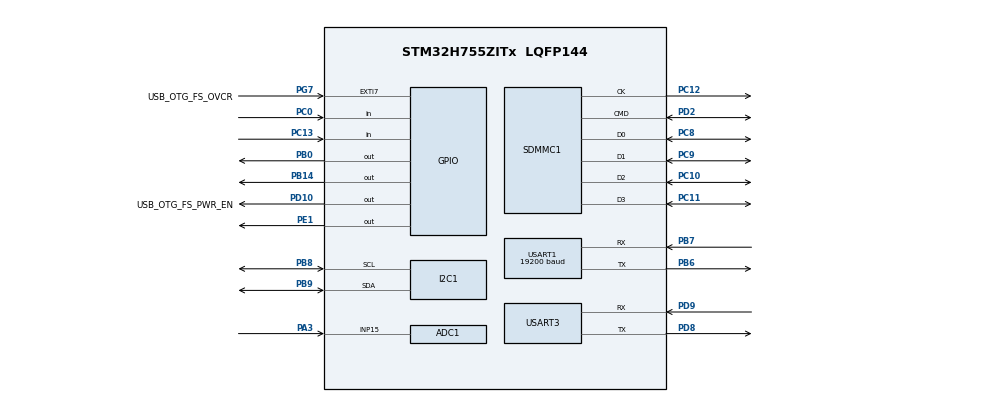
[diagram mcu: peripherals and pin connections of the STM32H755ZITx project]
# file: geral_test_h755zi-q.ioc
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ADC1.Channel-0\#ChannelRegularConversion=ADC_CHANNEL_15
ADC1.NbrOfConversionFlag=1
ADC1.OffsetNumber-0\#ChannelRegularConversion=ADC_OFFSET_NONE
ADC1.OffsetSignedSaturation-0\#ChannelRegularConversion=DISABLE
ADC1.Rank-0\#ChannelRegularConversion=1
ADC1.Resolution=ADC_RESOLUTION_8B
ADC1.SamplingTime-0\#ChannelRegularConversion=ADC_SAMPLETIME_1CYCLE_5
ADC1.master=1
CortexM4.IPs=FATFS_M4\:I,FREERTOS_M4\:I,IWDG2\:I,RCC,WWDG2\:I,DMA,BDMA,MDMA,NVIC2\:I,DEBUG,PDM2PCM_M4\:I,PWR,RESMGR_UTILITY,SYS_M4\:I,USB_DEVICE_M4\:I,USB_HOST_M4\:I,CORTEX_M4\:I,GPIO,OPENAMP_M4\:I,VREFBUF,NUCLEO-H755ZI-Q
CortexM7.IPs=FATFS_M7\:I,FREERTOS_M7\:I,IWDG1\:I,RCC\:I,WWDG1\:I,DMA\:I,BDMA\:I,MDMA\:I,NVIC1\:I,SYS\:I,CORTEX_M7\:I,DEBUG\:I,PDM2PCM_M7\:I,PWR\:I,RESMGR_UTILITY\:I,USB_DEVICE_M7\:I,USB_HOST_M7\:I,GPIO\:I,OPENAMP_M7\:I,VREFBUF\:I,NUCLEO-H755ZI-Q\:I,MEMORYMAP\:I,ADC1\:I,USART3\:I,TIM1\:I,USART1\:I,I2C1\:I,SDMMC1\:I
I2C1.Timing=0x00707CBB
Mcu.Family=STM32H7
Mcu.Name=STM32H755ZITx
Mcu.Package=LQFP144
NVIC1.PriorityGroup=NVIC_PRIORITYGROUP_4
NVIC1.USART1_IRQn=true\:0\:0\:false\:false\:true\:true\:true\:true
NVIC1.USART3_IRQn=true\:0\:0\:false\:false\:true\:true\:true\:true
NVIC2.PriorityGroup=NVIC_PRIORITYGROUP_4
PA1.PinAttribute=CortexM7
PA1.Signal=ETH_REF_CLK
PA11.PinAttribute=CortexM7
PA11.Signal=USB_OTG_FS_DM
PA12.PinAttribute=CortexM7
PA12.Signal=USB_OTG_FS_DP
PA2.PinAttribute=CortexM7
PA2.Signal=ETH_MDIO
PA3.PinAttribute=CortexM7
PA3.Signal=ADCx_INP15
PA7.PinAttribute=CortexM7
PA7.Signal=ETH_CRS_DV
PA8.PinAttribute=CortexM7
PA8.Signal=USB_OTG_FS_SOF
PA9.PinAttribute=CortexM7
PA9.Signal=USB_OTG_FS_VBUS
PB0.PinAttribute=Free
PB0.Signal=GPIO_Output
PB13.PinAttribute=CortexM7
PB13.Signal=ETH_TXD1
PB14.PinAttribute=Free
PB14.Signal=GPIO_Output
PB6.Mode=Asynchronous
PB6.PinAttribute=CortexM7
PB6.Signal=USART1_TX
PB7.Mode=Asynchronous
PB7.PinAttribute=CortexM7
PB7.Signal=USART1_RX
PB8.Mode=I2C
PB8.PinAttribute=CortexM7
PB8.Signal=I2C1_SCL
PB9.Mode=I2C
PB9.PinAttribute=CortexM7
PB9.Signal=I2C1_SDA
PC0.PinAttribute=Free
PC0.Signal=GPIO_Input
PC1.PinAttribute=CortexM7
PC1.Signal=ETH_MDC
PC10.Mode=SD_4_bits_Wide_bus
PC10.PinAttribute=CortexM7
PC10.Signal=SDMMC1_D2
PC11.Mode=SD_4_bits_Wide_bus
PC11.PinAttribute=CortexM7
PC11.Signal=SDMMC1_D3
PC12.Mode=SD_4_bits_Wide_bus
PC12.PinAttribute=CortexM7
PC12.Signal=SDMMC1_CK
PC13.PinAttribute=Free
PC13.Signal=GPIO_Input
PC14-OSC32_IN\ (OSC32_IN).PinAttribute=Free
PC14-OSC32_IN\ (OSC32_IN).Signal=RCC_OSC32_IN
PC15-OSC32_OUT\ (OSC32_OUT).PinAttribute=Free
PC15-OSC32_OUT\ (OSC32_OUT).Signal=RCC_OSC32_OUT
PC4.PinAttribute=CortexM7
PC4.Signal=ETH_RXD0
PC5.PinAttribute=CortexM7
PC5.Signal=ETH_RXD1
PC8.Mode=SD_4_bits_Wide_bus
PC8.PinAttribute=CortexM7
PC8.Signal=SDMMC1_D0
PC9.Mode=SD_4_bits_Wide_bus
PC9.PinAttribute=CortexM7
PC9.Signal=SDMMC1_D1
PD10.GPIO_Label=USB_OTG_FS_PWR_EN
PD10.PinAttribute=Free
PD10.Signal=GPIO_Output
PD2.Mode=SD_4_bits_Wide_bus
PD2.PinAttribute=CortexM7
PD2.Signal=SDMMC1_CMD
PD8.GPIO_ModeDefaultPP=GPIO_MODE_AF_PP
PD8.GPIO_PuPd=GPIO_NOPULL
PD8.GPIO_Speed=GPIO_SPEED_FREQ_LOW
PD8.Mode=Asynchronous
PD8.PinAttribute=CortexM7
PD8.Signal=USART3_TX
PD9.GPIO_ModeDefaultPP=GPIO_MODE_AF_PP
PD9.GPIO_PuPd=GPIO_NOPULL
PD9.GPIO_Speed=GPIO_SPEED_FREQ_LOW
PD9.Mode=Asynchronous
PD9.PinAttribute=CortexM7
PD9.Signal=USART3_RX
PE1.PinAttribute=Free
PE1.Signal=GPIO_Output
PG11.PinAttribute=CortexM7
PG11.Signal=ETH_TX_EN
PG12.PinAttribute=CortexM7
PG12.Signal=USART6_RTS
PG13.PinAttribute=CortexM7
PG13.Signal=ETH_TXD0
PG7.GPIO_Label=USB_OTG_FS_OVCR
PG7.PinAttribute=Free
PG7.Signal=GPXTI7
PG9.PinAttribute=CortexM7
PG9.Signal=USART6_RX
PH0-OSC_IN\ (PH0).PinAttribute=Free
PH0-OSC_IN\ (PH0).Signal=RCC_OSC_IN
PH1-OSC_OUT\ (PH1).PinAttribute=Free
PH1-OSC_OUT\ (PH1).Signal=RCC_OSC_OUT
ProjectManager.HeapSize=M4-0x200,M7-0x200
ProjectManager.StackSize=M4-0x400,M7-0x400
ProjectManager.TargetToolchain=STM32CubeIDE
RCC.ADCFreq_Value=80000000
RCC.APB1Freq_Value=32000000
RCC.APB2Freq_Value=32000000
RCC.APB3Freq_Value=64000000
RCC.APB4Freq_Value=64000000
RCC.CortexFreq_Value=64000000
RCC.D2PPRE1=RCC_APB1_DIV2
RCC.D2PPRE2=RCC_APB2_DIV2
RCC.DIVM1=4
RCC.DIVM2=4
RCC.DIVN1=10
RCC.DIVN2=10
RCC.HCLKFreq_Value=64000000
RCC.SYSCLKFreq_VALUE=64000000
RCC.SupplySource=PWR_DIRECT_SMPS_SUPPLY
RCC.USBFreq_Value=80000000
SH.ADCx_INP15.0=ADC1_INP15,IN15-Single-Ended
USART1.BaudRate=19200
USART1.VirtualMode-Asynchronous=VM_ASYNC
USART3.VirtualMode-Asynchronous=VM_ASYNC
VP_MEMORYMAP_VS_MEMORYMAP.Mode=CurAppReg
VP_SYS_M4_VS_Systick.Mode=SysTick
board=NUCLEO-H755ZI-Q

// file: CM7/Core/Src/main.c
/* USER CODE BEGIN Header */
/**
  ******************************************************************************
  * @file           : main.c
  * @brief          : Main program body
  ******************************************************************************
  * @attention
  *
  * Copyright (c) 2025 STMicroelectronics.
  * All rights reserved.
  *
  * This software is licensed under terms that can be found in the LICENSE file
  * in the root directory of this software component.
  * If no LICENSE file comes with this software, it is provided AS-IS.
  *
  ******************************************************************************
  */
/* USER CODE END Header */
#include "main.h"
#include "adc.h"
#include "i2c.h"
#include "memorymap.h"
#include "sdmmc.h"
#include "usart.h"
#include "gpio.h"

/* USER CODE BEGIN Includes */
#include "../../project/manager/manager.h"
/* USER CODE END Includes */

/* USER CODE BEGIN PD */

#ifndef HSEM_ID_0
#define HSEM_ID_0 (0U) /* HW semaphore 0*/
#endif

/* USER CODE END PD */

void SystemClock_Config(void);

int main(void)
{

/* USER CODE BEGIN Boot_Mode_Sequence_0 */
  int32_t timeout;
/* USER CODE END Boot_Mode_Sequence_0 */

/* USER CODE BEGIN Boot_Mode_Sequence_1 */
  /* Wait until CPU2 boots and enters in stop mode or timeout*/
  timeout = 0xFFFF;
  //while((__HAL_RCC_GET_FLAG(RCC_FLAG_D2CKRDY) != RESET) && (timeout-- > 0));
  //if ( timeout < 0 )
  //{
  //Error_Handler();
  //}
/* USER CODE END Boot_Mode_Sequence_1 */
  /* MCU Configuration--------------------------------------------------------*/

  /* Reset of all peripherals, Initializes the Flash interface and the Systick. */
  HAL_Init();

  /* Configure the system clock */
  SystemClock_Config();
/* USER CODE BEGIN Boot_Mode_Sequence_2 */
/* When system initialization is finished, Cortex-M7 will release Cortex-M4 by means of
HSEM notification */
/*HW semaphore Clock enable*/
__HAL_RCC_HSEM_CLK_ENABLE();
/*Take HSEM */
HAL_HSEM_FastTake(HSEM_ID_0);
/*Release HSEM in order to notify the CPU2(CM4)*/
HAL_HSEM_Release(HSEM_ID_0,0);
/* wait until CPU2 wakes up from stop mode */
timeout = 0xFFFF;
while((__HAL_RCC_GET_FLAG(RCC_FLAG_D2CKRDY) == RESET) && (timeout-- > 0));
if ( timeout < 0 )
{
Error_Handler();
}
/* USER CODE END Boot_Mode_Sequence_2 */

  /* Initialize all configured peripherals */
  MX_GPIO_Init();
  MX_USART3_UART_Init();
  MX_ADC1_Init();
  MX_USART1_UART_Init();
  MX_I2C1_Init();
  MX_SDMMC1_SD_Init();
  /* USER CODE BEGIN 2 */
  manager_init();
  /* USER CODE END 2 */

  /* Infinite loop */
  /* USER CODE BEGIN WHILE */
  while (1)
  {
	  manager_update();
    /* USER CODE END WHILE */

  }
}

void SystemClock_Config(void)
{
  RCC_OscInitTypeDef RCC_OscInitStruct = {0};
  RCC_ClkInitTypeDef RCC_ClkInitStruct = {0};

  /** Supply configuration update enable
  */
  HAL_PWREx_ConfigSupply(PWR_DIRECT_SMPS_SUPPLY);

  /** Configure the main internal regulator output voltage
  */
  __HAL_PWR_VOLTAGESCALING_CONFIG(PWR_REGULATOR_VOLTAGE_SCALE3);

  while(!__HAL_PWR_GET_FLAG(PWR_FLAG_VOSRDY)) {}

  /** Initializes the RCC Oscillators according to the specified parameters
  * in the RCC_OscInitTypeDef structure.
  */
  RCC_OscInitStruct.OscillatorType = RCC_OSCILLATORTYPE_HSI;
  RCC_OscInitStruct.HSIState = RCC_HSI_DIV1;
  RCC_OscInitStruct.HSICalibrationValue = RCC_HSICALIBRATION_DEFAULT;
  RCC_OscInitStruct.PLL.PLLState = RCC_PLL_ON;
  RCC_OscInitStruct.PLL.PLLSource = RCC_PLLSOURCE_HSI;
  RCC_OscInitStruct.PLL.PLLM = 4;
  RCC_OscInitStruct.PLL.PLLN = 10;
  RCC_OscInitStruct.PLL.PLLP = 2;
  RCC_OscInitStruct.PLL.PLLQ = 2;
  RCC_OscInitStruct.PLL.PLLR = 2;
  RCC_OscInitStruct.PLL.PLLRGE = RCC_PLL1VCIRANGE_3;
  RCC_OscInitStruct.PLL.PLLVCOSEL = RCC_PLL1VCOMEDIUM;
  RCC_OscInitStruct.PLL.PLLFRACN = 0;
  if (HAL_RCC_OscConfig(&RCC_OscInitStruct) != HAL_OK)
  {
    Error_Handler();
  }

  /** Initializes the CPU, AHB and APB buses clocks
  */
  RCC_ClkInitStruct.ClockType = RCC_CLOCKTYPE_HCLK|RCC_CLOCKTYPE_SYSCLK
                              |RCC_CLOCKTYPE_PCLK1|RCC_CLOCKTYPE_PCLK2
                              |RCC_CLOCKTYPE_D3PCLK1|RCC_CLOCKTYPE_D1PCLK1;
  RCC_ClkInitStruct.SYSCLKSource = RCC_SYSCLKSOURCE_HSI;
  RCC_ClkInitStruct.SYSCLKDivider = RCC_SYSCLK_DIV1;
  RCC_ClkInitStruct.AHBCLKDivider = RCC_HCLK_DIV1;
  RCC_ClkInitStruct.APB3CLKDivider = RCC_APB3_DIV1;
  RCC_ClkInitStruct.APB1CLKDivider = RCC_APB1_DIV2;
  RCC_ClkInitStruct.APB2CLKDivider = RCC_APB2_DIV2;
  RCC_ClkInitStruct.APB4CLKDivider = RCC_APB4_DIV1;

  if (HAL_RCC_ClockConfig(&RCC_ClkInitStruct, FLASH_LATENCY_1) != HAL_OK)
  {
    Error_Handler();
  }
}

void Error_Handler(void)
{
  __disable_irq();
  while (1)
  {
  }
}
